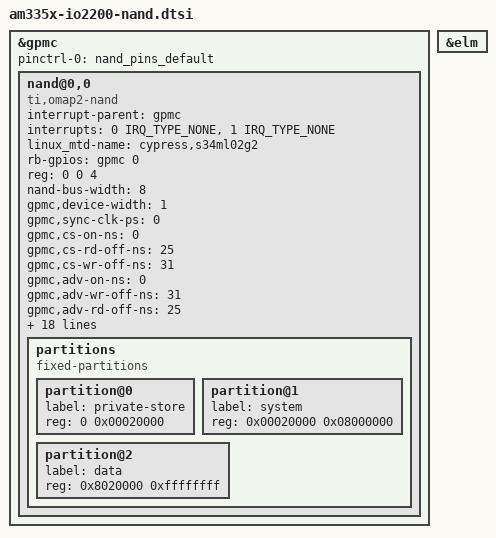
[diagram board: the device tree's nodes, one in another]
#include <dt-bindings/interrupt-controller/irq.h>

&gpmc {
	status = "okay";
	pinctrl-names = "default";
	pinctrl-0 = <&nand_pins_default>;

	ranges = <0 0 0x08000000 0x08000000>;   /* CS0: NAND */

	nand@0,0 {
               compatible = "ti,omap2-nand";
               interrupt-parent = <&gpmc>;
               interrupts = <0 IRQ_TYPE_NONE>, <1 IRQ_TYPE_NONE>;
               linux_mtd-name = "cypress,s34ml02g2";
               rb-gpios = <&gpmc 0 GPIO_ACTIVE_HIGH>; /* gpmc_wait0 */
		reg = <0 0 4>; /* CS0, offset 0 */
		nand-bus-width = <8>;
		gpmc,device-width = <1>;        /* 8 bits data bus for S34ML01G200TFI000 */
		gpmc,sync-clk-ps = <0>;         /* Nandflash bus is asynchronous - don't care */        
		gpmc,cs-on-ns = <0>;            /* not needed: CS starts cycle*/
		gpmc,cs-rd-off-ns = <25>;       /* Nandflash timing tRC */
		gpmc,cs-wr-off-ns = <31>;       /* Nandflash timing tWC */        
		gpmc,adv-on-ns = <0>;           /* not needed: ADVn/ALE synchronous with CS)*/
		gpmc,adv-wr-off-ns = <31>;      /* Nandflash timing tALS+tALH (keep synchronous as CS */        
		gpmc,adv-rd-off-ns = <25>;      /* Nandflash timing tALS+tALH (read access with ALE does not exist - don't care) */                        
		gpmc,we-on-ns = <0>;            /* not needed: WEn synchronous with CS*/
		gpmc,we-off-ns = <12>;          /* Nandflash timing tWP */        
		gpmc,oe-on-ns = <0>;            /* not needed: WEn synchronous with CS*/
		gpmc,oe-off-ns = <15>;          /* Nandflash tming ??? */
		gpmc,access-ns = <20>;          /* Nandflash timing tREA */    
		gpmc,rd-cycle-ns = <25>;        /* Nandflash timing tRC */
		gpmc,wr-cycle-ns = <31>;        /* Nandflash timing tWC */               
		/*gpmc,wait-on-read */
		/*gpmc,wait-on-write */                
		gpmc,bus-turnaround-ns = <0>;       /* already included in above calculation */
		gpmc,cycle2cycle-delay-ns = <61>;  /* Nandflash timing tWHR */
		gpmc,clk-activation-ns = <0>;       /* not used with asynchronous bus */
		gpmc,wait-monitoring-ns = <0>;      /* Not used */   
		gpmc,wr-access-ns = <20>;           /* Nandflash timing tREA??? */
		gpmc,wr-data-mux-bus-ns = <0>;      /*not used with non muliplexed bus*/                
		ti,nand-ecc-opt= "bch8";
		ti,elm-id = <&elm>;

		/* gpmc,page-burst-access-ns = <??> */  /*not used with asynchronous bus*/
		/* gpmc,adv-extra-delay */              /*omitted to set is as false*/
		/* gpmc,cs-extra-delay  */              /*omitted to set is as false*/
		/* gpmc,cycle2cycle-diffcsen */         /*omitted to set it as false: single part is used on GPMC*/
		gpmc,cycle2cycle-samecsen;              /* Required by tWHR2 nandflash timing*/
		/* gpmc,oe-extra-delay */               /*omitted to set is as false*/
		gpmc,we-extra-delay;                  /* add extra delay on WEn to guaranty tCLS and tWH)
		/* gpmc,time-para-granularity */        /*omitted to set is as false*/
		/* gpmc,burst-length = <??> */          /*not used with asynchronous bus*/
		/* gpmc,burst-wrap = <??> */            /*not used with asynchronous bus*/
		/* gpmc,burst-read = <??> */            /*not used with asynchronous bus*/
		/* gpmc,burst-write = <??> */           /*not used with asynchronous bus*/
		/* gpmc,mux-add-data = <??> */          /*not used with non muliplexed bus*/
		/* gpmc,sync-read = <??> */             /*not used with asynchronous bus*/
		/* gpmc,sync-write = <??> */            /*not used with asynchronous bus*/

		gpmc,wait-pin = <0> ;/* 0: wait0 pin */

#address-cells = <1>;
#size-cells = <1>;                            

		partitions {
			compatible = "fixed-partitions";
#address-cells = <1>;
#size-cells = <1>;

			partition@0 {
				label = "private-store";
				reg   = <0 0x00020000>;
			};
			partition@1 {
				label = "system";
				reg   = <0x00020000 0x08000000>;
			};
			partition@2 {
				label = "data";
				reg   = <0x8020000 0xffffffff>;
			};
		};
	};
};
&elm {
	status = "okay";
};
